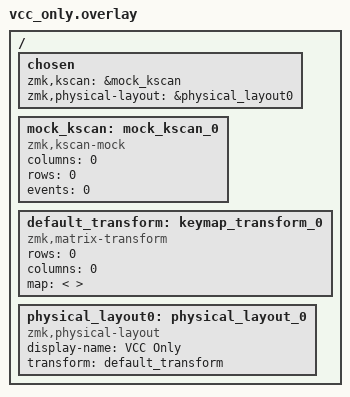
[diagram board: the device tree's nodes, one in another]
#include <dt-bindings/zmk/matrix_transform.h>

/ {
    chosen {
        zmk,kscan = &mock_kscan;
        zmk,physical-layout = &physical_layout0;
    };

    mock_kscan: mock_kscan_0 {
        compatible = "zmk,kscan-mock";
        columns = <0>;
        rows = <0>;
        events = <0>;
    };

    default_transform: keymap_transform_0 {
        compatible = "zmk,matrix-transform";
        rows = <0>;
        columns = <0>;
        map = <
        >;
    };

    physical_layout0: physical_layout_0 {
        compatible = "zmk,physical-layout";
        display-name = "VCC Only";
        transform = <&default_transform>;
    };
};
